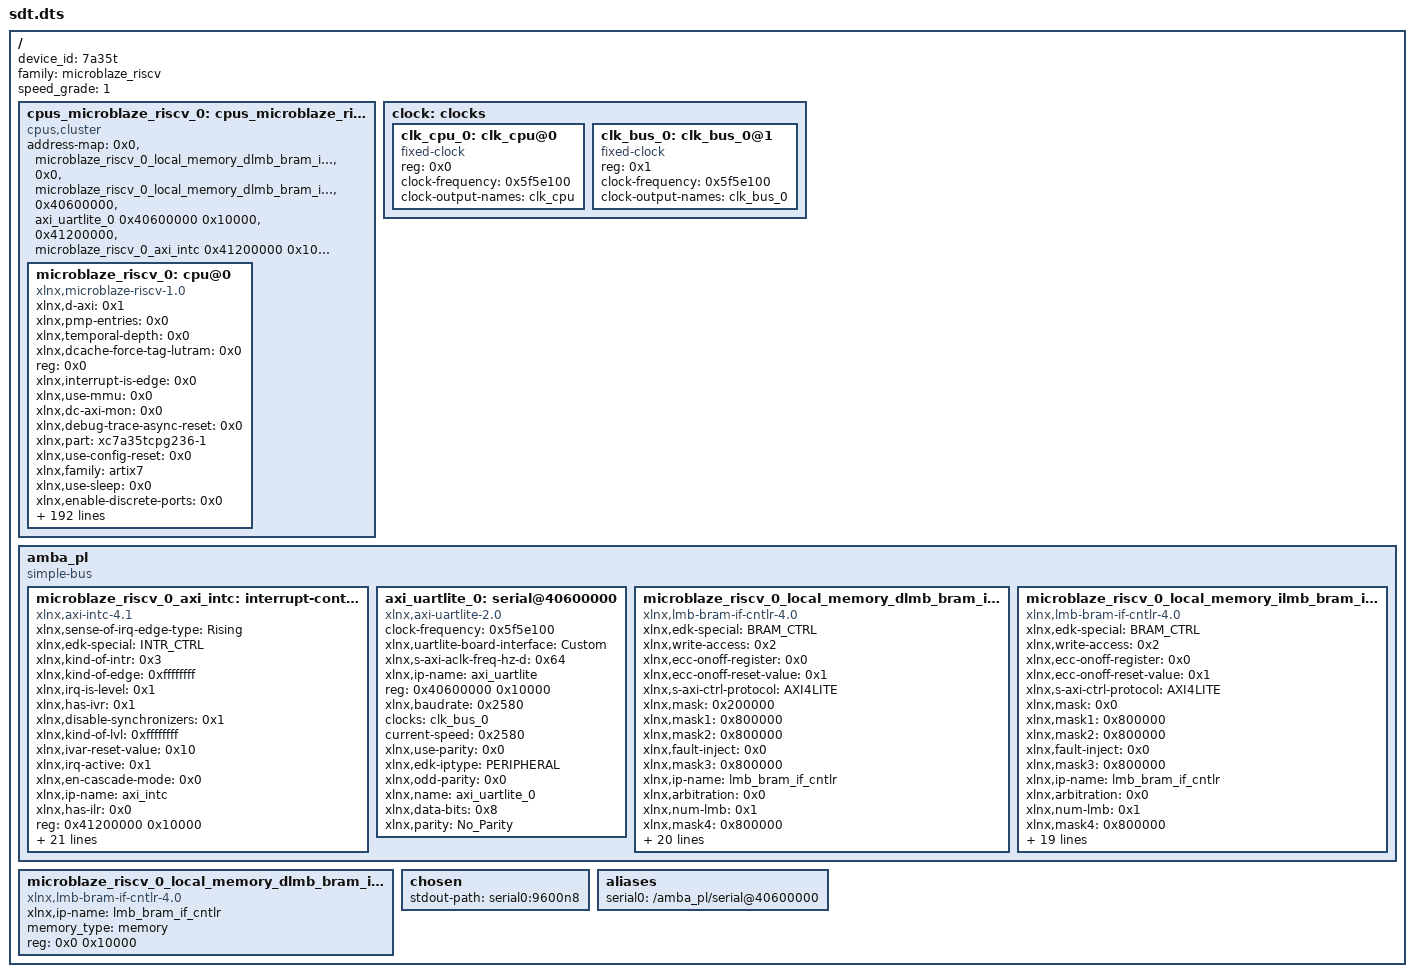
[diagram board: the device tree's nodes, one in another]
/dts-v1/;
/ {
        device_id = "7a35t";
        #address-cells = <0x1>;
        #size-cells = <0x1>;
        family = "microblaze_riscv";
        speed_grade = "1";

        cpus_microblaze_riscv_0: cpus_microblaze_riscv@0 {
                #cpu-mask-cells = <0x1>;
                compatible = "cpus,cluster";
                #address-cells = <0x1>;
                #size-cells = <0x0>;
                address-map = <0x0 &microblaze_riscv_0_local_memory_dlmb_bram_if_cntlr_memory 0x0 0x10000>,
                 <0x0 &microblaze_riscv_0_local_memory_dlmb_bram_if_cntlr 0x0 0x10000>,
                 <0x40600000 &axi_uartlite_0 0x40600000 0x10000>,
                 <0x41200000 &microblaze_riscv_0_axi_intc 0x41200000 0x10000>;
                #ranges-address-cells = <0x1>;
                #ranges-size-cells = <0x1>;
                phandle = <0x7>;

                microblaze_riscv_0: cpu@0 {
                        xlnx,d-axi = <0x1>;
                        xlnx,pmp-entries = <0x0>;
                        xlnx,temporal-depth = <0x0>;
                        xlnx,dcache-force-tag-lutram = <0x0>;
                        reg = <0x0>;
                        xlnx,interrupt-is-edge = <0x0>;
                        xlnx,use-mmu = <0x0>;
                        xlnx,dc-axi-mon = <0x0>;
                        xlnx,debug-trace-async-reset = <0x0>;
                        xlnx,part = "xc7a35tcpg236-1";
                        xlnx,use-config-reset = <0x0>;
                        xlnx,family = "artix7";
                        xlnx,use-sleep = <0x0>;
                        xlnx,enable-discrete-ports = <0x0>;
                        xlnx,d-lmb = <0x1>;
                        xlnx,debug-interface = <0x0>;
                        xlnx,use-ext-brk = <0x0>;
                        xlnx,debug-enabled = <0x1>;
                        xlnx,daddr-size = <0x20>;
                        xlnx,use-extended-fsl-instr = <0x0>;
                        xlnx,branch-target-cache-size = <0x0>;
                        bus-handle = <0x5>;
                        xlnx,pmp-addr0 = <0x0>;
                        xlnx,pmp-addr1 = <0x0>;
                        xlnx,pmp-addr2 = <0x0>;
                        xlnx,pmp-addr3 = <0x0>;
                        xlnx,pmp-addr4 = <0x0>;
                        xlnx,edk-special = "microblaze_riscv";
                        xlnx,pmp-addr5 = <0x0>;
                        xlnx,use-dcache = <0x0>;
                        xlnx,use-muldiv = <0x2>;
                        xlnx,pmp-addr6 = <0x0>;
                        xlnx,use-axi-dp-ext-addr = <0x0>;
                        xlnx,pmp-addr7 = <0x0>;
                        xlnx,pmp-addr8 = <0x0>;
                        xlnx,pmp-addr9 = <0x0>;
                        xlnx,i-axi = <0x0>;
                        xlnx,icache-streams = <0x0>;
                        xlnx,num-sync-ff-dbg-clk = <0x1>;
                        xlnx,icache-byte-size = <0x1000>;
                        xlnx,pmp-addr10 = <0x0>;
                        d-cache-size = <0x1000>;
                        xlnx,pmp-addr11 = <0x0>;
                        xlnx,pmp-addr12 = <0x0>;
                        xlnx,pmp-addr13 = <0x0>;
                        xlnx,pmp-addr14 = <0x0>;
                        xlnx,pmp-addr15 = <0x0>;
                        xlnx,avoid-primitives = <0x0>;
                        xlnx,pmp-addr16 = <0x0>;
                        xlnx,pmp-addr17 = <0x0>;
                        xlnx,pmp-addr18 = <0x0>;
                        xlnx,pdaddr-size = <0x20>;
                        xlnx,pmp-addr19 = <0x0>;
                        xlnx,pmp-addr20 = <0x0>;
                        xlnx,pmp-addr21 = <0x0>;
                        xlnx,i-lmb = <0x1>;
                        xlnx,pmp-addr22 = <0x0>;
                        xlnx,lmb-data-size = <0x20>;
                        xlnx,lockstep-select = <0x0>;
                        xlnx,pmp-addr23 = <0x0>;
                        timebase-frequency = <0x5f5e100>;
                        xlnx,pmp-addr24 = <0x0>;
                        xlnx,dcache-data-width = <0x0>;
                        xlnx,icache-force-tag-lutram = <0x0>;
                        xlnx,pmp-addr25 = <0x0>;
                        xlnx,pmp-addr26 = <0x0>;
                        xlnx,use-branch-target-cache = <0x0>;
                        xlnx,pmp-addr27 = <0x0>;
                        xlnx,number-of-pc-brk = <0x1>;
                        xlnx,pmp-addr28 = <0x0>;
                        xlnx,imprecise-exceptions = <0x0>;
                        xlnx,pmp-addr29 = <0x0>;
                        xlnx,pmp-addr30 = <0x0>;
                        xlnx,pmp-addr31 = <0x0>;
                        xlnx,pmp-addr32 = <0x0>;
                        model = "microblaze_riscv,1.0";
                        xlnx,pmp-addr33 = <0x0>;
                        xlnx,pmp-addr34 = <0x0>;
                        xlnx,pmp-addr35 = <0x0>;
                        xlnx,pmp-addr36 = <0x0>;
                        d-cache-highaddr = <0x3fffffff>;
                        xlnx,optimization = <0x1>;
                        xlnx,pmp-addr37 = <0x0>;
                        xlnx,pmp-addr38 = <0x0>;
                        xlnx,pmp-addr39 = <0x0>;
                        xlnx,pmp-addr40 = <0x0>;
                        xlnx,pmp-addr41 = <0x0>;
                        xlnx,d-lmb-mon = <0x0>;
                        xlnx,pmp-addr42 = <0x0>;
                        xlnx,pmp-addr43 = <0x0>;
                        xlnx,pmp-addr44 = <0x0>;
                        xlnx,pmp-addr45 = <0x0>;
                        xlnx,pmp-addr46 = <0x0>;
                        xlnx,pmp-addr47 = <0x0>;
                        xlnx,pmp-addr48 = <0x0>;
                        xlnx,fault-tolerant = <0x0>;
                        xlnx,pmp-addr49 = <0x0>;
                        xlnx,pmp-addr50 = <0x0>;
                        xlnx,pmp-addr51 = <0x0>;
                        xlnx,pmp-enhancements = <0x0>;
                        d-cache-line-size = <0x10>;
                        xlnx,mmu-privileged-instr = <0x0>;
                        xlnx,pmp-addr52 = <0x0>;
                        clock-frequency = <0x5f5e100>;
                        xlnx,pmp-addr53 = <0x0>;
                        xlnx,pmp-addr54 = <0x0>;
                        xlnx,pmp-addr55 = <0x0>;
                        xlnx,i-lmb-protocol = <0x0>;
                        xlnx,pmp-addr56 = <0x0>;
                        xlnx,pmp-addr57 = <0x0>;
                        xlnx,dp-axi-mon = <0x0>;
                        xlnx,pmp-addr58 = <0x0>;
                        xlnx,pmp-addr59 = <0x0>;
                        xlnx,pmp-addr60 = <0x0>;
                        xlnx,pmp-addr61 = <0x0>;
                        xlnx,pmp-addr62 = <0x0>;
                        xlnx,pmp-addr63 = <0x0>;
                        xlnx,debug-external-trace = <0x0>;
                        xlnx,addr-size = <0x20>;
                        xlnx,debug-event-counters = <0x0>;
                        xlnx,edk-iptype = "PROCESSOR";
                        xlnx,debug-latency-counters = <0x0>;
                        xlnx,interconnect = <0x2>;
                        xlnx,edge-is-positive = <0x1>;
                        xlnx,use-icache = <0x0>;
                        xlnx,async-wakeup = <0x3>;
                        xlnx,s-axi = <0x0>;
                        xlnx,use-ext-nm-brk = <0x0>;
                        xlnx,ic-axi-mon = <0x0>;
                        xlnx,archid = <0x1>;
                        xlnx,num-sync-ff-clk-irq = <0x1>;
                        xlnx,freq = <0x5f5e100>;
                        xlnx,lockstep-master = <0x0>;
                        xlnx,pmp-cfg0 = <0x0>;
                        xlnx,pmp-cfg1 = <0x0>;
                        xlnx,iaddr-size = <0x20>;
                        xlnx,interrupt-mon = <0x0>;
                        xlnx,pmp-cfg2 = <0x0>;
                        xlnx,number-of-wr-addr-brk = <0x0>;
                        xlnx,pmp-cfg3 = <0x0>;
                        xlnx,pmp-cfg4 = <0x0>;
                        xlnx,use-interrupt = <0x2>;
                        xlnx,pmp-cfg5 = <0x0>;
                        xlnx,async-interrupt = <0x1>;
                        xlnx,pc-width = <0x10>;
                        xlnx,pmp-cfg6 = <0x0>;
                        xlnx,icache-victims = <0x0>;
                        xlnx,pmp-cfg7 = <0x0>;
                        xlnx,pmp-cfg8 = <0x0>;
                        xlnx,pmp-cfg9 = <0x0>;
                        xlnx,use-bitman-a = <0x0>;
                        xlnx,use-bitman-b = <0x0>;
                        xlnx,use-bitman-c = <0x0>;
                        xlnx,i-lmb-mon = <0x0>;
                        xlnx,dcache-byte-size = <0x1000>;
                        xlnx,data-size = <0x20>;
                        compatible = "xlnx,microblaze-riscv-1.0", "xlnx,microblaze_riscv";
                        xlnx,pmp-debug-inhibit = <0x0>;
                        xlnx,fsl-exception = <0x0>;
                        xlnx,dcache-use-writeback = <0x0>;
                        device_type = "cpu";
                        xlnx,impid = <0x1>;
                        xlnx,use-bitman-s = <0x0>;
                        xlnx,base-vectors = <0x0>;
                        xlnx,icache-line-len = <0x4>;
                        xlnx,use-barrel = <0x1>;
                        xlnx,misaligned-exceptions = <0x1>;
                        xlnx,piaddr-size = <0x20>;
                        xlnx,use-bitman = <0x0>;
                        xlnx,dcache-line-len = <0x4>;
                        xlnx,num-sync-ff-clk = <0x2>;
                        xlnx,memory-ip-list = "microblaze_riscv_0_local_memory_ilmb_bram_if_cntlr_memory", "microblaze_riscv_0_local_memory_dlmb_bram_if_cntlr_memory";
                        xlnx,number-of-rd-addr-brk = <0x0>;
                        xlnx,lockstep-slave = <0x0>;
                        xlnx,use-counters = <0x1>;
                        interrupt-handle = <0x4>;
                        xlnx,pmp-cfg10 = <0x0>;
                        xlnx,pmp-cfg11 = <0x0>;
                        xlnx,debug-profile-size = <0x0>;
                        xlnx,pmp-cfg12 = <0x0>;
                        xlnx,pmp-cfg13 = <0x0>;
                        xlnx,pmp-cfg14 = <0x0>;
                        xlnx,pmp-cfg15 = <0x0>;
                        xlnx,debug-counter-width = <0x40>;
                        xlnx,icache-data-width = <0x0>;
                        xlnx,ip-name = "microblaze_riscv";
                        xlnx,ip-axi-mon = <0x0>;
                        xlnx,d-lmb-protocol = <0x0>;
                        xlnx,trace = <0x0>;
                        xlnx,ill-instr-exception = <0x1>;
                        xlnx,debug-trace-size = <0x0>;
                        xlnx,pmp-granularity = <0x2>;
                        xlnx,num-sync-ff-dbg-trace-clk = <0x2>;
                        xlnx,ecc-use-ce-exception = <0x0>;
                        xlnx,num-sync-ff-clk-debug = <0x2>;
                        xlnx,use-atomic = <0x0>;
                        xlnx,g-template-list = <0x1>;
                        xlnx,hartid = <0x0>;
                        xlnx,use-fpu = <0x0>;
                        xlnx,use-non-secure = <0x0>;
                        d-cache-baseaddr = <0x0>;
                        xlnx,use-compression = <0x1>;
                        xlnx,instr-size = <0x20>;
                        xlnx,fsl-links = <0x0>;
                        xlnx,dcache-victims = <0x0>;
                        xlnx,pmp-read-only = <0x0>;
                        phandle = <0x8>;
                };
        };

        clock: clocks {
                #address-cells = <0x1>;
                #size-cells = <0x0>;
                phandle = <0x9>;

                clk_cpu_0: clk_cpu@0 {
                        compatible = "fixed-clock";
                        reg = <0x0>;
                        clock-frequency = <0x5f5e100>;
                        clock-output-names = "clk_cpu";
                        #clock-cells = <0x0>;
                        phandle = <0xa>;
                };

                clk_bus_0: clk_bus_0@1 {
                        compatible = "fixed-clock";
                        reg = <0x1>;
                        clock-frequency = <0x5f5e100>;
                        clock-output-names = "clk_bus_0";
                        #clock-cells = <0x0>;
                        phandle = <0x6>;
                };
        };

        amba_pl: amba_pl {
                ranges;
                compatible = "simple-bus";
                #address-cells = <0x1>;
                #size-cells = <0x1>;
                phandle = <0x5>;

                microblaze_riscv_0_axi_intc: interrupt-controller@41200000 {
                        #interrupt-cells = <0x2>;
                        xlnx,sense-of-irq-edge-type = "Rising";
                        xlnx,edk-special = "INTR_CTRL";
                        xlnx,kind-of-intr = <0x3>;
                        xlnx,kind-of-edge = <0xffffffff>;
                        xlnx,irq-is-level = <0x1>;
                        xlnx,has-ivr = <0x1>;
                        compatible = "xlnx,axi-intc-4.1", "xlnx,xps-intc-1.00.a";
                        xlnx,disable-synchronizers = <0x1>;
                        xlnx,kind-of-lvl = <0xffffffff>;
                        xlnx,ivar-reset-value = <0x10>;
                        xlnx,irq-active = <0x1>;
                        xlnx,en-cascade-mode = <0x0>;
                        xlnx,ip-name = "axi_intc";
                        xlnx,has-ilr = <0x0>;
                        reg = <0x41200000 0x10000>;
                        xlnx,addr-width = <0x20>;
                        xlnx,s-axi-aclk-freq-mhz = <0x64>;
                        xlnx,num-sw-intr = <0x0>;
                        xlnx,irq-connection = <0x0>;
                        xlnx,num-intr-inputs = <0x2>;
                        xlnx,has-sie = <0x1>;
                        xlnx,enable-async = <0x0>;
                        xlnx,has-cie = <0x1>;
                        xlnx,num-sync-ff = <0x2>;
                        xlnx,edk-iptype = "PERIPHERAL";
                        xlnx,mb-clk-not-connected = <0x1>;
                        xlnx,has-ipr = <0x1>;
                        xlnx,sense-of-irq-level-type = "Active_High";
                        xlnx,cascade-master = <0x0>;
                        xlnx,processor-clk-freq-mhz = <0x64>;
                        status = "okay";
                        xlnx,is-fast = <0x1>;
                        xlnx,has-fast = <0x1>;
                        xlnx,ivar-rst-val = <0x10>;
                        interrupt-controller;
                        xlnx,async-intr = <0xffffffff>;
                        xlnx,name = "microblaze_riscv_0_axi_intc";
                        phandle = <0x4>;
                };

                axi_uartlite_0: serial@40600000 {
                        compatible = "xlnx,axi-uartlite-2.0", "xlnx,xps-uartlite-1.00.a";
                        clock-frequency = <0x5f5e100>;
                        xlnx,uartlite-board-interface = "Custom";
                        xlnx,s-axi-aclk-freq-hz-d = <0x64>;
                        xlnx,ip-name = "axi_uartlite";
                        reg = <0x40600000 0x10000>;
                        xlnx,baudrate = <0x2580>;
                        clocks = <&clk_bus_0>;
                        current-speed = <0x2580>;
                        xlnx,use-parity = <0x0>;
                        xlnx,edk-iptype = "PERIPHERAL";
                        xlnx,odd-parity = <0x0>;
                        status = "okay";
                        xlnx,name = "axi_uartlite_0";
                        xlnx,data-bits = <0x8>;
                        xlnx,parity = "No_Parity";
                        phandle = <0x3>;
                };

                microblaze_riscv_0_local_memory_dlmb_bram_if_cntlr: lmb_bram_if_cntlr@0 {
                        xlnx,edk-special = "BRAM_CTRL";
                        xlnx,write-access = <0x2>;
                        compatible = "xlnx,lmb-bram-if-cntlr-4.0", "xlnx,axi-bram-ctrl";
                        xlnx,ecc-onoff-register = <0x0>;
                        xlnx,ecc-onoff-reset-value = <0x1>;
                        xlnx,s-axi-ctrl-protocol = "AXI4LITE";
                        xlnx,mask = <0x200000>;
                        xlnx,mask1 = <0x800000>;
                        xlnx,mask2 = <0x800000>;
                        xlnx,fault-inject = <0x0>;
                        xlnx,mask3 = <0x800000>;
                        xlnx,ip-name = "lmb_bram_if_cntlr";
                        xlnx,arbitration = <0x0>;
                        xlnx,num-lmb = <0x1>;
                        xlnx,mask4 = <0x800000>;
                        reg = <0x0 0x10000>;
                        xlnx,s-axi-ctrl-addr-width = <0x20>;
                        xlnx,mask5 = <0x800000>;
                        xlnx,ecc-status-registers = <0x0>;
                        xlnx,mask6 = <0x800000>;
                        xlnx,lmb-protocol = <0x0>;
                        xlnx,ce-counter-width = <0x0>;
                        xlnx,mask7 = <0x800000>;
                        xlnx,ecc = <0x0>;
                        xlnx,edk-iptype = "PERIPHERAL";
                        xlnx,lmb-dwidth = <0x20>;
                        xlnx,interconnect = <0x0>;
                        xlnx,ce-failing-registers = <0x0>;
                        xlnx,ue-failing-registers = <0x0>;
                        status = "okay";
                        xlnx,data-width = <0x20>;
                        xlnx,s-axi-ctrl-data-width = <0x20>;
                        xlnx,bram-awidth = <0x20>;
                        xlnx,lmb-awidth = <0x20>;
                        xlnx,name = "microblaze_riscv_0_local_memory_dlmb_bram_if_cntlr";
                        phandle = <0x2>;
                };

                microblaze_riscv_0_local_memory_ilmb_bram_if_cntlr: lmb_bram_if_cntlr@1 {
                        xlnx,edk-special = "BRAM_CTRL";
                        xlnx,write-access = <0x2>;
                        compatible = "xlnx,lmb-bram-if-cntlr-4.0", "xlnx,axi-bram-ctrl";
                        xlnx,ecc-onoff-register = <0x0>;
                        xlnx,ecc-onoff-reset-value = <0x1>;
                        xlnx,s-axi-ctrl-protocol = "AXI4LITE";
                        xlnx,mask = <0x0>;
                        xlnx,mask1 = <0x800000>;
                        xlnx,mask2 = <0x800000>;
                        xlnx,fault-inject = <0x0>;
                        xlnx,mask3 = <0x800000>;
                        xlnx,ip-name = "lmb_bram_if_cntlr";
                        xlnx,arbitration = <0x0>;
                        xlnx,num-lmb = <0x1>;
                        xlnx,mask4 = <0x800000>;
                        reg = <0x0 0x10000>;
                        xlnx,s-axi-ctrl-addr-width = <0x20>;
                        xlnx,mask5 = <0x800000>;
                        xlnx,ecc-status-registers = <0x0>;
                        xlnx,mask6 = <0x800000>;
                        xlnx,lmb-protocol = <0x0>;
                        xlnx,ce-counter-width = <0x0>;
                        xlnx,mask7 = <0x800000>;
                        xlnx,ecc = <0x0>;
                        xlnx,edk-iptype = "PERIPHERAL";
                        xlnx,lmb-dwidth = <0x20>;
                        xlnx,interconnect = <0x0>;
                        xlnx,ce-failing-registers = <0x0>;
                        xlnx,ue-failing-registers = <0x0>;
                        status = "okay";
                        xlnx,s-axi-ctrl-data-width = <0x20>;
                        xlnx,bram-awidth = <0x20>;
                        xlnx,lmb-awidth = <0x20>;
                        xlnx,name = "microblaze_riscv_0_local_memory_ilmb_bram_if_cntlr";
                        phandle = <0xb>;
                };
        };

        microblaze_riscv_0_local_memory_dlmb_bram_if_cntlr_memory: memory@0 {
                compatible = "xlnx,lmb-bram-if-cntlr-4.0";
                xlnx,ip-name = "lmb_bram_if_cntlr";
                device_type = "memory";
                memory_type = "memory";
                reg = <0x0 0x10000>;
                phandle = <0x1>;
        };

        chosen {
                stdout-path = "serial0:9600n8";
        };

        aliases {
                serial0 = "/amba_pl/serial@40600000";
        };

        __symbols__ {
                cpus_microblaze_riscv_0 = "/cpus_microblaze_riscv@0";
                microblaze_riscv_0 = "/cpus_microblaze_riscv@0/cpu@0";
                clock = "/clocks";
                clk_cpu_0 = "/clocks/clk_cpu@0";
                clk_bus_0 = "/clocks/clk_bus_0@1";
                amba_pl = "/amba_pl";
                microblaze_riscv_0_axi_intc = "/amba_pl/interrupt-controller@41200000";
                axi_uartlite_0 = "/amba_pl/serial@40600000";
                microblaze_riscv_0_local_memory_dlmb_bram_if_cntlr = "/amba_pl/lmb_bram_if_cntlr@0";
                microblaze_riscv_0_local_memory_ilmb_bram_if_cntlr = "/amba_pl/lmb_bram_if_cntlr@1";
                microblaze_riscv_0_local_memory_dlmb_bram_if_cntlr_memory = "/memory@0";
        };
};
